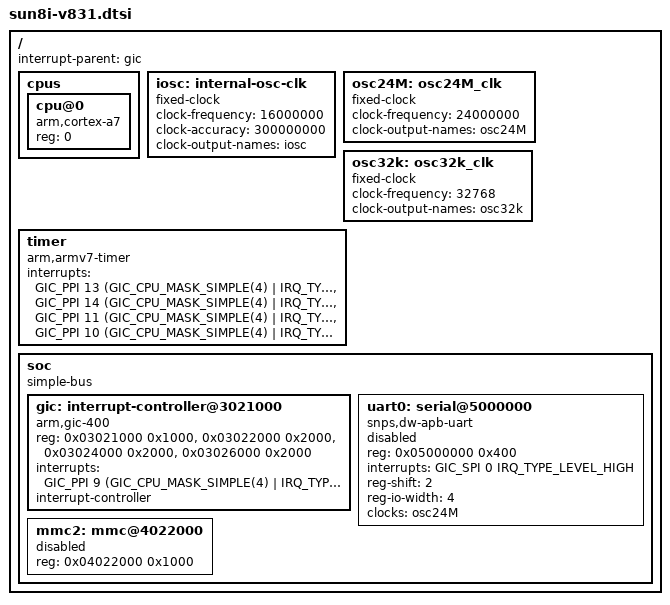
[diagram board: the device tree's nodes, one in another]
// SPDX-License-Identifier: (GPL-2.0+ or MIT)
/*
 * Copyright (C) 2020 Icenowy Zheng <icenowy@aosc.io>
 */

#include <dt-bindings/interrupt-controller/arm-gic.h>

/ {
	interrupt-parent = <&gic>;
	#address-cells = <1>;
	#size-cells = <1>;

	cpus {
		#address-cells = <1>;
		#size-cells = <0>;

		cpu@0 {
			compatible = "arm,cortex-a7";
			device_type = "cpu";
			reg = <0>;
		};
	};

	iosc: internal-osc-clk {
		#clock-cells = <0>;
		compatible = "fixed-clock";
		clock-frequency = <16000000>;
		clock-accuracy = <300000000>;
		clock-output-names = "iosc";
	};

	osc24M: osc24M_clk {
		#clock-cells = <0>;
		compatible = "fixed-clock";
		clock-frequency = <24000000>;
		clock-output-names = "osc24M";
	};

	osc32k: osc32k_clk {
		#clock-cells = <0>;
		compatible = "fixed-clock";
		clock-frequency = <32768>;
		clock-output-names = "osc32k";
	};

	timer {
		compatible = "arm,armv7-timer";
		interrupts = <GIC_PPI 13 (GIC_CPU_MASK_SIMPLE(4) | IRQ_TYPE_LEVEL_LOW)>,
			     <GIC_PPI 14 (GIC_CPU_MASK_SIMPLE(4) | IRQ_TYPE_LEVEL_LOW)>,
			     <GIC_PPI 11 (GIC_CPU_MASK_SIMPLE(4) | IRQ_TYPE_LEVEL_LOW)>,
			     <GIC_PPI 10 (GIC_CPU_MASK_SIMPLE(4) | IRQ_TYPE_LEVEL_LOW)>;
	};

	soc {
		compatible = "simple-bus";
		#address-cells = <1>;
		#size-cells = <1>;
		ranges;

		gic: interrupt-controller@3021000 {
			compatible = "arm,gic-400";
			reg = <0x03021000 0x1000>,
			      <0x03022000 0x2000>,
			      <0x03024000 0x2000>,
			      <0x03026000 0x2000>;
			interrupts = <GIC_PPI 9 (GIC_CPU_MASK_SIMPLE(4) | IRQ_TYPE_LEVEL_HIGH)>;
			interrupt-controller;
			#interrupt-cells = <3>;
		};

		uart0: serial@5000000 {
			compatible = "snps,dw-apb-uart";
			reg = <0x05000000 0x400>;
			interrupts = <GIC_SPI 0 IRQ_TYPE_LEVEL_HIGH>;
			reg-shift = <2>;
			reg-io-width = <4>;
			clocks = <&osc24M>;
			status = "disabled";
		};

		mmc2: mmc@4022000 {
			reg = <0x04022000 0x1000>;
			status = "disabled";
		};
	};
};
